# CANFD0_1.0 register map
Vendor: Texas Instruments
Registers are 32-bit, read-write, no defined reset value unless marked. A register's access mark holds for its fields unless they carry their own. Offsets are as the file gives them; [hi:lo] are bit positions; lines under a group give offsets from that group; {n}, {i} and the like mark numbered series.

## CANFD0 (part 2 of 3)
0x7000 CANFD0_MCAN group
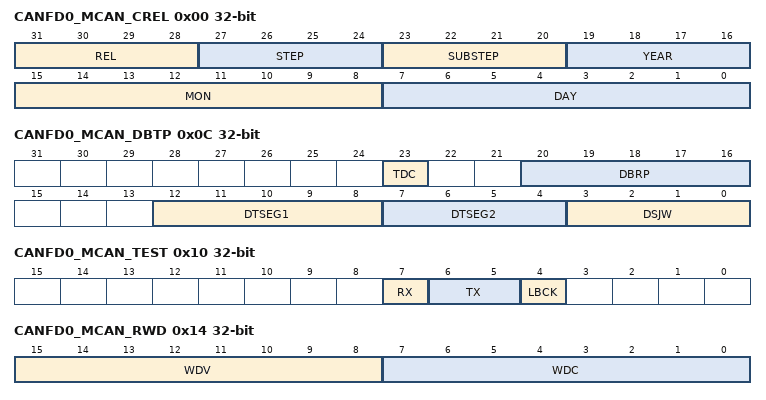
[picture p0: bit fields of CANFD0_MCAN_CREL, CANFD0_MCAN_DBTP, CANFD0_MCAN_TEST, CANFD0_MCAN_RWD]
  0x00 CANFD0_MCAN_CREL ro — MCAN Core Release Register
    [31:28] REL — Core Release. One digit, BCD-coded.
    [27:24] STEP — Step of Core Release. One digit, BCD-coded.
    [23:20] SUBSTEP — Sub-Step of Core Release. One digit, BCD-coded.
    [19:16] YEAR — Time Stamp Year. One digit, BCD-coded.
    [15:8] MON — Time Stamp Month. Two digits, BCD-coded.
    [7:0] DAY — Time Stamp Day. Two digits, BCD-coded.
  0x04 CANFD0_MCAN_ENDN access not given — MCAN Endian Register
  0x0C CANFD0_MCAN_DBTP — MCAN Data Bit Timing and Prescaler Register
    [23] TDC — Transmitter Delay Compensation 0 Transmitter Delay Compensation disabled 1 Transmitter Delay Compensation enabled
    [20:16] DBRP — Data Bit Rate Prescaler. The value by which the oscillator frequency is divided for generating the bit time quanta. The bit time is built up from a multiple of this quanta. Valid values for the Bit Rate Prescaler are 0 to 31. The actual interpretation by the hardware of this value is such that one more than the value programmed here is used. Qualified Write is possible only with CCCR.CCE='1' and CCCR.INIT='1'.
    [12:8] DTSEG1 — Data Time Segment Before Sample Point. Valid values are 0 to 31. The actual interpretation by the hardware of this value is such that one more than the programmed value is used. Qualified Write is possible only with CCCR.CCE='1' and CCCR.INIT='1'.
    [7:4] DTSEG2 — Data Time Segment After Sample Point. Valid values are 0 to 15. The actual interpretation by the hardware of this value is such that one more than the programmed value is used. Qualified Write is possible only with CCCR.CCE='1' and CCCR.INIT='1'.
    [3:0] DSJW — Data Resynchronization Jump Width. Valid values are 0 to 15. The actual interpretation by the hardware of this value is such that one more than the value programmed here is used. Qualified Write is possible only with CCCR.CCE='1' and CCCR.INIT='1'.
  0x10 CANFD0_MCAN_TEST access per field — MCAN Test Register
    [7] RX ro — Receive Pin. Monitors the actual value of the CAN receive pin.
      0=DOMINANT (The CAN bus is dominant (CAN RX pin = '0')); 1=RECESSIVE (The CAN bus is recessive (CAN RX pin = '1'))
    [6:5] TX rw — Control of Transmit Pin 00 CAN TX pin controlled by the CAN Core, updated at the end of the CAN bit time 01 Sample Point can be monitored at CAN TX pin 10 Dominant ('0') level at CAN TX pin 11 Recessive ('1') at CAN TX pin Qualified Write is possible only with CCCR.CCE='1' and CCCR.INIT='1'.
    [4] LBCK rw — Loop Back Mode. Qualified Write is possible only with CCCR.CCE='1' and CCCR.INIT='1'.
      0=DISABLE (Reset value, Loop Back Mode is disabled); 1=ENABLE (Loop Back Mode is enabled)
  0x14 CANFD0_MCAN_RWD access per field — MCAN RAM Watchdog
    [15:8] WDV ro — Watchdog Value. Acutal Message RAM Watchdog Counter Value. The RAM Watchdog monitors the READY output of the Message RAM. A Message RAM access via the MCAN's Generic Master Interface starts the Message RAM Watchdog Counter with the value configured by the WDC field. The counter is reloaded with WDC when the Message RAM signals successful completion by activating its READY output. In case there is no response from the Message RAM until the counter has counted down to zero, the counter stops and interrupt flag MCAN_IR.WDI is set. The RAM Watchdog Counter is clocked by the host (system) clock.
    [7:0] WDC rw — Watchdog Configuration. Start value of the Message RAM Watchdog Counter. With the reset value of "00" the counter is disabled. Qualified Write is possible only with CCCR.CCE='1' and CCCR.INIT='1'.
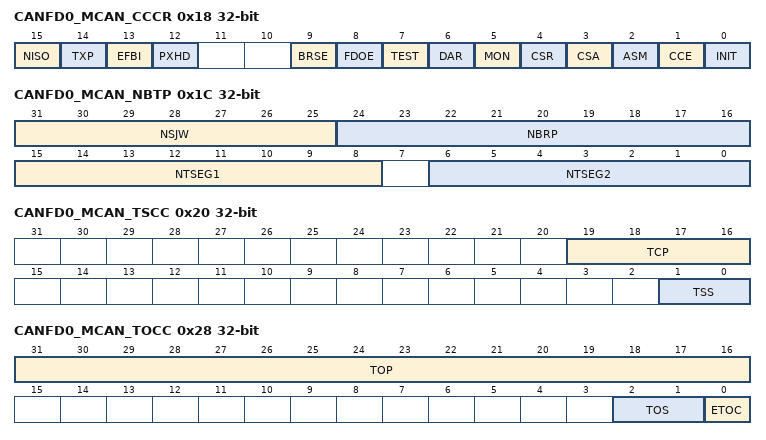
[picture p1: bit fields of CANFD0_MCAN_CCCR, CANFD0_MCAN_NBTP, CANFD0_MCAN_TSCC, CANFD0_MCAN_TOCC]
  0x18 CANFD0_MCAN_CCCR access per field — MCAN CC Control Register
    [15] NISO rw — Non ISO Operation. If this bit is set, the MCAN uses the CAN FD frame format as specified by the Bosch CAN FD Specification V1.0. 0 CAN FD frame format according to ISO 11898-1:2015 1 CAN FD frame format according to Bosch CAN FD Specification V1.0
    [14] TXP rw — Transmit Pause. If this bit is set, the MCAN pauses for two CAN bit times before starting the next transmission after itself has successfully transmitted a frame. 0 Transmit pause disabled 1 Transmit pause enabled Qualified Write is possible only with CCCR.CCE='1' and CCCR.INIT='1'.
    [13] EFBI rw — Edge Filtering during Bus Integration 0 Edge filtering disabled 1 Two consecutive dominant tq required to detect an edge for hard synchronization Qualified Write is possible only with CCCR.CCE='1' and CCCR.INIT='1'.
    [12] PXHD rw — Protocol Exception Handling Disable 0 Protocol exception handling enabled 1 Protocol exception handling disabled Note: When protocol exception handling is disabled, the MCAN will transmit an error frame when it detects a protocol exception condition. Qualified Write is possible only with CCCR.CCE='1' and CCCR.INIT='1'.
    [9] BRSE rw — Bit Rate Switch Enable 0 Bit rate switching for transmissions disabled 1 Bit rate switching for transmissions enabled Note: When CAN FD operation is disabled FDOE = '0', BRSE is not evaluated. Qualified Write is possible only with CCCR.CCE='1' and CCCR.INIT='1'.
    [8] FDOE rw — Flexible Datarate Operation Enable 0 FD operation disabled 1 FD operation enabled Qualified Write is possible only with CCCR.CCE='1' and CCCR.INIT='1'.
    [7] TEST rw — Test Mode Enable 0 Normal operation, register TEST holds reset values 1 Test Mode, write access to register TEST enabled Qualified Write 1 to Set is possible only with CCCR.CCE='1' and CCCR.INIT='1'.
    [6] DAR rw — Disable Automatic Retransmission 0 Automatic retransmission of messages not transmitted successfully enabled 1 Automatic retransmission disabled Qualified Write is possible only with CCCR.CCE='1' and CCCR.INIT='1'.
    [5] MON rw — Bus Monitoring Mode. Bit MON can only be set by SW when both CCE and INIT are set to '1'. The bit can be reset by SW at any time. 0 Bus Monitoring Mode is disabled 1 Bus Monitoring Mode is enabled Qualified Write 1 to Set is possible only with CCCR.CCE='1' and CCCR.INIT='1'.
    [4] CSR rw — Clock Stop Request 0 No clock stop is requested 1 Clock stop requested. When clock stop is requested, first INIT and then CSA will be set after all pending transfer requests have been completed and the CAN bus reached idle.
    [3] CSA ro — Clock Stop Acknowledge 0 No clock stop acknowledged 1 MCAN may be set in power down by stopping the Host and CAN clocks
    [2] ASM rw — Restricted Operation Mode. Bit ASM can only be set by SW when both CCE and INIT are set to '1'. The bit can be reset by SW at any time. 0 Normal CAN operation 1 Restricted Operation Mode active Qualified Write 1 to Set is possible only with CCCR.CCE='1' and CCCR.INIT='1'.
    [1] CCE rw — Configuration Change Enable 0 The CPU has no write access to the protected configuration registers 1 The CPU has write access to the protected configuration registers (while CCCR.INIT = '1') Qualified Write is possible only with CCCR.CCE='1' and CCCR.INIT='1'.
    [0] INIT rw — Initialization 0 Normal Operation 1 Initialization is started Note: Due to the synchronization mechanism between the two clock domains, there may be a delay until the value written to INIT can be read back. Therefore the programmer has to assure that the previous value written to INIT has been accepted by reading INIT before setting INIT to a new value.
  0x1C CANFD0_MCAN_NBTP — MCAN Nominal Bit Timing and Prescaler Register
    [31:25] NSJW — Nominal (Re)Synchronization Jump Width. Valid values are 0 to 127. The actual interpretation by the hardware of this value is such that one more than the value programmed here is used. Qualified Write is possible only with CCCR.CCE='1' and CCCR.INIT='1'.
    [24:16] NBRP — Nominal Bit Rate Prescaler. The value by which the oscillator frequency is divided for generating the bit time quanta. The bit time is built up from a multiple of this quanta. Valid values for the Bit Rate Prescaler are 0 to 511. The actual interpretation by the hardware of this value is such that one more than the value programmed here is used. Qualified Write is possible only with CCCR.CCE='1' and CCCR.INIT='1'.
    [15:8] NTSEG1 — Nominal Time Segment Before Sample Point. Valid values are 1 to 255. The actual interpretation by the hardware of this value is such that one more than the programmed value is used. Qualified Write is possible only with CCCR.CCE='1' and CCCR.INIT='1'.
    [6:0] NTSEG2 — Nominal Time Segment After Sample Point. Valid values are 1 to 127. The actual interpretation by the hardware of this value is such that one more than the programmed value is used. Qualified Write is possible only with CCCR.CCE='1' and CCCR.INIT='1'.
  0x20 CANFD0_MCAN_TSCC — MCAN Timestamp Counter Configuration
    [19:16] TCP — Timestamp Counter Prescaler. Configures the timestamp and timeout counters time unit in multiples of CAN bit times. Valid values are 0 to 15. The actual interpretation by the hardware of this value is such that one more than the value programmed here is used. Note: With CAN FD an external counter is required for timestamp generation (TSS = "10"). Qualified Write is possible only with CCCR.CCE='1' and CCCR.INIT='1'.
    [1:0] TSS — Timestamp Select 00 Timestamp counter value always 0x0000 01 Timestamp counter value incremented according to TCP 10 External timestamp counter value used 11 Same as "00" Qualified Write is possible only with CCCR.CCE='1' and CCCR.INIT='1'.
  0x24 CANFD0_MCAN_TSCV — MCAN Timestamp Counter Value
    [15:0] TSC — Timestamp Counter. The internal/external Timestamp Counter value is captured on start of frame (both Rx and Tx). When TSCC.TSS = "01", the Timestamp Counter is incremented in multiples of CAN bit times, (1...16), depending on the configuration of TSCC.TCP. A wrap around sets interrupt flag IR.TSW. Write access resets the counter to zero. When TSCC.TSS = "10", TSC reflects the External Timestamp Counter value, and a write access has no impact. Note: A "wrap around" is a change of the Timestamp Counter value from non-zero to zero not caused by write access to MCAN_TSCV.
  0x28 CANFD0_MCAN_TOCC — MCAN Timeout Counter Configuration
    [31:16] TOP — Timeout Period. Start value of the Timeout Counter (down-counter). Configures the Timeout Period. Qualified Write is possible only with CCCR.CCE='1' and CCCR.INIT='1'.
    [2:1] TOS — Timeout Select. When operating in Continuous mode, a write to TOCV presets the counter to the value configured by TOCC.TOP and continues down-counting. When the Timeout Counter is controlled by one of the FIFOs, an empty FIFO presets the counter to the value configured by TOCC.TOP. Down-counting is started when the first FIFO element is stored. 00 Continuous operation 01 Timeout controlled by Tx Event FIFO 10 Timeout controlled by Rx FIFO 0 11 Timeout controlled by Rx FIFO 1 Qualified Write is possible only with CCCR.CCE='1' and CCCR.INIT='1'.
    [0] ETOC — Enable Timeout Counter 0 Timeout Counter disabled 1 Timeout Counter enabled Qualified Write is possible only with CCCR.CCE='1' and CCCR.INIT='1'.
  0x2C CANFD0_MCAN_TOCV — MCAN Timeout Counter Value
    [15:0] TOC — Timeout Counter. The Timeout Counter is decremented in multiples of CAN bit times, (1...16), depending on the configuration of TSCC.TCP. When decremented to zero, interrupt flag IR.TOO is set and the Timeout Counter is stopped. Start and reset/restart conditions are configured via TOCC.TOS.
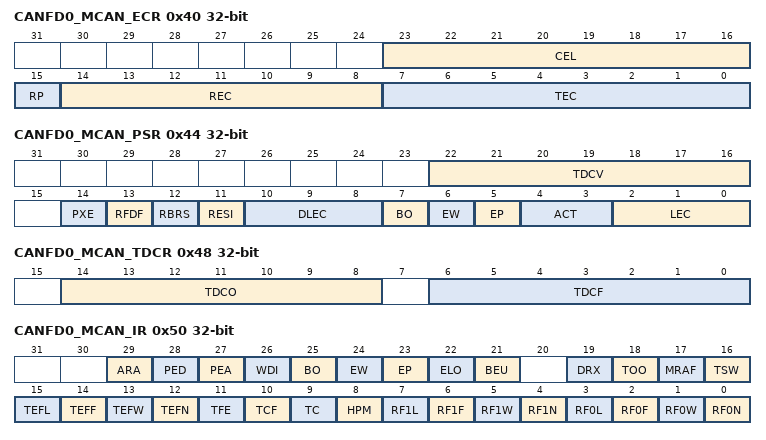
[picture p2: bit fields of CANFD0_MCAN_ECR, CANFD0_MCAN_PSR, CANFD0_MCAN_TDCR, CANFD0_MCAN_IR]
  0x40 CANFD0_MCAN_ECR ro — MCAN Error Counter Register
    [23:16] CEL — CAN Error Logging. The counter is incremented each time when a CAN protocol error causes the Transmit Error Counter or the Receive Error Counter to be incremented. It is reset by read access to CEL. The counter stops at 0xFF; the next increment of TEC or REC sets interrupt flag IR.ELO. Note: When CCCR.ASM is set, the CAN protocol controller does not increment TEC and REC when a CAN protocol error is detected, but CEL is still incremented.
    [15] RP — Receive Error Passive 0 The Receive Error Counter is below the error passive level of 128 1 The Receive Error Counter has reached the error passive level of 128
    [14:8] REC — Receive Error Counter. Actual state of the Receive Error Counter, values between 0 and 127. Note: When CCCR.ASM is set, the CAN protocol controller does not increment TEC and REC when a CAN protocol error is detected, but CEL is still incremented.
    [7:0] TEC — Transmit Error Counter. Actual state of the Transmit Error Counter, values between 0 and 255. Note: When CCCR.ASM is set, the CAN protocol controller does not increment TEC and REC when a CAN protocol error is detected, but CEL is still incremented.
  0x44 CANFD0_MCAN_PSR ro — MCAN Protocol Status Register
    [22:16] TDCV — Transmitter Delay Compensation Value. Position of the secondary sample point, defined by the sum of the measured delay from the internal CAN TX signal to the internal CAN RX signal and TDCR.TDCO. The SSP position is, in the data phase, the number of mtq between the start of the transmitted bit and the secondary sample point. Valid values are 0 to 127 mtq.
    [14] PXE — Protocol Exception Event 0 No protocol exception event occurred since last read access 1 Protocol exception event occurred
    [13] RFDF — Received a CAN FD Message. This bit is set independent of acceptance filtering. 0 Since this bit was reset by the CPU, no CAN FD message has been received 1 Message in CAN FD format with FDF flag set has been received
    [12] RBRS — BRS Flag of Last Received CAN FD Message. This bit is set together with RFDF, independent of acceptance filtering. 0 Last received CAN FD message did not have its BRS flag set 1 Last received CAN FD message had its BRS flag set
    [11] RESI — ESI Flag of Last Received CAN FD Message. This bit is set together with RFDF, independent of acceptance filtering. 0 Last received CAN FD message did not have its ESI flag set 1 Last received CAN FD message had its ESI flag set
    [10:8] DLEC — Data Phase Last Error Code. Type of last error that occurred in the data phase of a CAN FD format frame with its BRS flag set. Coding is the same as for LEC. This field will be cleared to zero when a CAN FD format frame with its BRS flag set has been transferred (reception or transmission) without error.
    [7] BO — Bus_Off Status 0 The M_CAN is not Bus_Off 1 The M_CAN is in Bus_Off state
    [6] EW — Warning Status 0 Both error counters are below the Error_Warning limit of 96 1 At least one of error counter has reached the Error_Warning limit of 96
    [5] EP — Error Passive 0 The M_CAN is in the Error_Active state. It normally takes part in bus communication and sends an active error flag when an error has been detected 1 The M_CAN is in the Error_Passive state
    [4:3] ACT — Node Activity. Monitors the module's CAN communication state. 00 Synchronizing - node is synchronizing on CAN communication 01 Idle - node is neither receiver nor transmitter 10 Receiver - node is operating as receiver 11 Transmitter - node is operating as transmitter Note: ACT is set to "00" by a Protocol Exception Event.
    [2:0] LEC — Last Error Code. The LEC indicates the type of the last error to occur on the CAN bus. This field will be cleared to '0' when a message has been transferred (reception or transmission) without error. 0 No Error: No error occurred since LEC has been reset by successful reception or transmission. 1 Stuff Error: More than 5 equal bits in a sequence have occurred in a part of a received message where this is not allowed. 2 Form Error: A fixed format part of a received frame has the wrong format. 3 AckError: The message transmitted by the MCAN was not acknowledged by another node. 4 Bit1Error: During the transmission of a message (with the exception of the arbitration field), the device wanted to send a recessive level (bit of logical value '1'), but the monitored bus value was dominant. 5 Bit0Error: During the transmission of a message (or acknowledge bit, or active error flag, or overload flag), the device wanted to send a dominant level (data or identifier bit logical value '0'), but the monitored bus value was recessive. During Bus_Off recovery this status is set each time a sequence of 11 recessive bits has been monitored. This enables the CPU to monitor the proceeding of the Bus_Off recovery sequence (indicating the bus is not stuck at dominant or continuously disturbed). 6 CRCError: The CRC check sum of a received message was incorrect. The CRC of an incoming message does not match with the CRC calculated from the received data. 7 NoChange: Any read access to the Protocol Status Register re-initializes the LEC to '7'. When the LEC shows the value '7', no CAN bus event was detected since the last CPU read access to the Protocol Status Register. Note: When a frame in CAN FD format has reached the data phase with BRS flag set, the next CAN event (error or valid frame) will be shown in DLEC instead of LEC. An error in a fixed stuff bit of a CAN FD CRC sequence will be shown as a Form Error, not Stuff Error. Note: The Bus_Off recovery sequence (see ISO 11898-1:2015) cannot be shortened by setting or resetting CCCR.INIT. If the device goes Bus_Off, it will set CCCR.INIT of its own accord, stopping all bus activities. Once CCCR.INIT has been cleared by the CPU, the device will then wait for 129 occurrences of Bus Idle (129 * 11 consecutive recessive bits) before resuming normal operation. At the end of the Bus_Off recovery sequence, the Error Management Counters will be reset. During the waiting time after the resetting of CCCR.INIT, each time a sequence of 11 recessive bits has been monitored, a Bit0Error code is written to PSR.LEC, enabling the CPU to readily check up whether the CAN bus is stuck at dominant or continuously disturbed and to monitor the Bus_Off recovery sequence. ECR.REC is used to count these sequences.
  0x48 CANFD0_MCAN_TDCR — MCAN Transmitter Delay Compensation Register
    [14:8] TDCO — Transmitter Delay Compensation Offset. Offset value defining the distance between the measured delay from the internal CAN TX signal to the internal CAN RX signal and the secondary sample point. Valid values are 0 to 127 mtq. Qualified Write is possible only with CCCR.CCE='1' and CCCR.INIT='1'.
    [6:0] TDCF — Transmitter Delay Compensation Filter Window Length. Defines the minimum value for the SSP position, dominant edges on the internal CAN RX signal that would result in an earlier SSP position are ignored for transmitter delay measurement. The feature is enabled when TDCF is configured to a value greater than TDCO. Valid values are 0 to 127 mtq. Qualified Write is possible only with CCCR.CCE='1' and CCCR.INIT='1'.
  0x50 CANFD0_MCAN_IR — MCAN Interrupt Register
    [29] ARA — Access to Reserved Address 0 No access to reserved address occurred 1 Access to reserved address occurred
    [28] PED — Protocol Error in Data Phase (Data Bit Time is used) 0 No protocol error in data phase 1 Protocol error in data phase detected (PSR.DLEC ? 0,7)
    [27] PEA — Protocol Error in Arbitration Phase (Nominal Bit Time is used) 0 No protocol error in arbitration phase 1 Protocol error in arbitration phase detected (PSR.LEC ? 0,7)
    [26] WDI — Watchdog Interrupt 0 No Message RAM Watchdog event occurred 1 Message RAM Watchdog event due to missing READY
    [25] BO — Bus_Off Status 0 Bus_Off status unchanged 1 Bus_Off status changed
    [24] EW — Warning Status 0 Error_Warning status unchanged 1 Error_Warning status changed
    [23] EP — Error Passive 0 Error_Passive status unchanged 1 Error_Passive status changed
    [22] ELO — Error Logging Overflow 0 CAN Error Logging Counter did not overflow 1 Overflow of CAN Error Logging Counter occurred
    [21] BEU — Bit Error Uncorrected. Message RAM bit error detected, uncorrected. This bit is set when a double bit error is detected by the ECC aggregator attached to the Message RAM. An uncorrected Message RAM bit error sets CCCR.INIT to '1'. This is done to avoid transmission of corrupted data. 0 No bit error detected when reading from Message RAM 1 Bit error detected, uncorrected (e.g. parity logic)
    [19] DRX — Message Stored to Dedicated Rx Buffer. The flag is set whenever a received message has been stored into a dedicated Rx Buffer. 0 No Rx Buffer updated 1 At least one received message stored into an Rx Buffer
    [18] TOO — Timeout Occurred 0 No timeout 1 Timeout reached
    [17] MRAF — Message RAM Access Failure. The flag is set, when the Rx Handler: - has not completed acceptance filtering or storage of an accepted message until the arbitration field of the following message has been received. In this case acceptance filtering or message storage is aborted and the Rx Handler starts processing of the following message. - was not able to write a message to the Message RAM. In this case message storage is aborted. In both cases the FIFO put index is not updated resp. the New Data flag for a dedicated Rx Buffer is not set, a partly stored message is overwritten when the next message is stored to this location. The flag is also set when the Tx Handler was not able to read a message from the Message RAM in time. In this case message transmission is aborted. In case of a Tx Handler access failure the MCAN is switched into Restricted Operation Mode. To leave Restricted Operation Mode, the Host CPU has to reset CCCR.ASM. 0 No Message RAM access failure occurred 1 Message RAM access failure occurred
    [16] TSW — Timestamp Wraparound 0 No timestamp counter wrap-around 1 Timestamp counter wrapped around
    [15] TEFL — Tx Event FIFO Element Lost 0 No Tx Event FIFO element lost 1 Tx Event FIFO element lost, also set after write attempt to Tx Event FIFO of size zero
    [14] TEFF — Tx Event FIFO Full 0 Tx Event FIFO not full 1 Tx Event FIFO full
    [13] TEFW — Tx Event FIFO Watermark Reached 0 Tx Event FIFO fill level below watermark 1 Tx Event FIFO fill level reached watermark
    [12] TEFN — Tx Event FIFO New Entry 0 Tx Event FIFO unchanged 1 Tx Handler wrote Tx Event FIFO element
    [11] TFE — Tx FIFO Empty 0 Tx FIFO non-empty 1 Tx FIFO empty
    [10] TCF — Transmission Cancellation Finished 0 No transmission cancellation finished 1 Transmission cancellation finished
    [9] TC — Transmission Completed 0 No transmission completed 1 Transmission completed
    [8] HPM — High Priority Message 0 No high priority message received 1 High priority message received
    [7] RF1L — Rx FIFO 1 Message Lost 0 No Rx FIFO 1 message lost 1 Rx FIFO 1 message lost, also set after write attempt to Rx FIFO 1 of size zero
    [6] RF1F — Rx FIFO 1 Full 0 Rx FIFO 1 not full 1 Rx FIFO 1 full
    [5] RF1W — Rx FIFO 1 Watermark Reached 0 Rx FIFO 1 fill level below watermark 1 Rx FIFO 1 fill level reached watermark
    [4] RF1N — Rx FIFO 1 New Message 0 No new message written to Rx FIFO 1 1 New message written to Rx FIFO 1
    [3] RF0L — Rx FIFO 0 Message Lost 0 No Rx FIFO 0 message lost 1 Rx FIFO 0 message lost, also set after write attempt to Rx FIFO 0 of size zero
    [2] RF0F — Rx FIFO 0 Full 0 Rx FIFO 0 not full 1 Rx FIFO 0 full
    [1] RF0W — Rx FIFO 0 Watermark Reached 0 Rx FIFO 0 fill level below watermark 1 Rx FIFO 0 fill level reached watermark
    [0] RF0N — Rx FIFO 0 New Message 0 No new message written to Rx FIFO 0 1 New message written to Rx FIFO 0
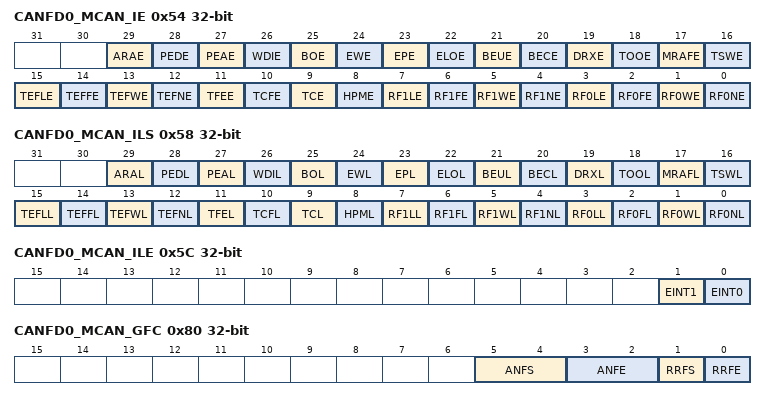
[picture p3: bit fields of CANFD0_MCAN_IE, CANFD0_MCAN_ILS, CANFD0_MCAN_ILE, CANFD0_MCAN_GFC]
  0x54 CANFD0_MCAN_IE — MCAN Interrupt Enable
    [29] ARAE — Access to Reserved Address Enable
    [28] PEDE — Protocol Error in Data Phase Enable
    [27] PEAE — Protocol Error in Arbitration Phase Enable
    [26] WDIE — Watchdog Interrupt Enable
    [25] BOE — Bus_Off Status Enable
    [24] EWE — Warning Status Enable
    [23] EPE — Error Passive Enable
    [22] ELOE — Error Logging Overflow Enable
    [21] BEUE — Bit Error Uncorrected Enable
    [20] BECE — Bit Error Corrected Enable A separate interrupt line reserved for corrected bit errors is provided via the MCAN_ERROR_REGS. It advised for the user to use these registers and leave this bit cleared to '0'.
    [19] DRXE — Message Stored to Dedicated Rx Buffer Enable
    [18] TOOE — Timeout Occurred Enable
    [17] MRAFE — Message RAM Access Failure Enable
    [16] TSWE — Timestamp Wraparound Enable
    [15] TEFLE — Tx Event FIFO Element Lost Enable
    [14] TEFFE — Tx Event FIFO Full Enable
    [13] TEFWE — Tx Event FIFO Watermark Reached Enable
    [12] TEFNE — Tx Event FIFO New Entry Enable
    [11] TFEE — Tx FIFO Empty Enable
    [10] TCFE — Transmission Cancellation Finished Enable
    [9] TCE — Transmission Completed Enable
    [8] HPME — High Priority Message Enable
    [7] RF1LE — Rx FIFO 1 Message Lost Enable
    [6] RF1FE — Rx FIFO 1 Full Enable
    [5] RF1WE — Rx FIFO 1 Watermark Reached Enable
    [4] RF1NE — Rx FIFO 1 New Message Enable
    [3] RF0LE — Rx FIFO 0 Message Lost Enable
    [2] RF0FE — Rx FIFO 0 Full Enable
    [1] RF0WE — Rx FIFO 0 Watermark Reached Enable
    [0] RF0NE — Rx FIFO 0 New Message Enable
  0x58 CANFD0_MCAN_ILS — MCAN Interrupt Line Select
    [29] ARAL — Access to Reserved Address Line 0 Interrupt source is assigned to Interrupt Line 0 1 Interrupt source is assigned to Interrupt Line 1
    [28] PEDL — Protocol Error in Data Phase Line 0 Interrupt source is assigned to Interrupt Line 0 1 Interrupt source is assigned to Interrupt Line 1
    [27] PEAL — Protocol Error in Arbitration Phase Line 0 Interrupt source is assigned to Interrupt Line 0 1 Interrupt source is assigned to Interrupt Line 1
    [26] WDIL — Watchdog Interrupt Line 0 Interrupt source is assigned to Interrupt Line 0 1 Interrupt source is assigned to Interrupt Line 1
    [25] BOL — Bus_Off Status Line 0 Interrupt source is assigned to Interrupt Line 0 1 Interrupt source is assigned to Interrupt Line 1
    [24] EWL — Warning Status Line 0 Interrupt source is assigned to Interrupt Line 0 1 Interrupt source is assigned to Interrupt Line 1
    [23] EPL — Error Passive Line 0 Interrupt source is assigned to Interrupt Line 0 1 Interrupt source is assigned to Interrupt Line 1
    [22] ELOL — Error Logging Overflow Line 0 Interrupt source is assigned to Interrupt Line 0 1 Interrupt source is assigned to Interrupt Line 1
    [21] BEUL — Bit Error Uncorrected Line 0 Interrupt source is assigned to Interrupt Line 0 1 Interrupt source is assigned to Interrupt Line 1
    [20] BECL — Bit Error Corrected Line A separate interrupt line reserved for corrected bit errors is provided via the MCAN_ERROR_REGS. It advised for the user to use these registers and leave the MCAN_IE.BECE bit cleared to '0' (disabled), thereby relegating this bit to not applicable.
    [19] DRXL — Message Stored to Dedicated Rx Buffer Line 0 Interrupt source is assigned to Interrupt Line 0 1 Interrupt source is assigned to Interrupt Line 1
    [18] TOOL — Timeout Occurred Line 0 Interrupt source is assigned to Interrupt Line 0 1 Interrupt source is assigned to Interrupt Line 1
    [17] MRAFL — Message RAM Access Failure Line 0 Interrupt source is assigned to Interrupt Line 0 1 Interrupt source is assigned to Interrupt Line 1
    [16] TSWL — Timestamp Wraparound Line 0 Interrupt source is assigned to Interrupt Line 0 1 Interrupt source is assigned to Interrupt Line 1
    [15] TEFLL — Tx Event FIFO Element Lost Line 0 Interrupt source is assigned to Interrupt Line 0 1 Interrupt source is assigned to Interrupt Line 1
    [14] TEFFL — Tx Event FIFO Full Line 0 Interrupt source is assigned to Interrupt Line 0 1 Interrupt source is assigned to Interrupt Line 1
    [13] TEFWL — Tx Event FIFO Watermark Reached Line 0 Interrupt source is assigned to Interrupt Line 0 1 Interrupt source is assigned to Interrupt Line 1
    [12] TEFNL — Tx Event FIFO New Entry Line 0 Interrupt source is assigned to Interrupt Line 0 1 Interrupt source is assigned to Interrupt Line 1
    [11] TFEL — Tx FIFO Empty Line 0 Interrupt source is assigned to Interrupt Line 0 1 Interrupt source is assigned to Interrupt Line 1
    [10] TCFL — Transmission Cancellation Finished Line 0 Interrupt source is assigned to Interrupt Line 0 1 Interrupt source is assigned to Interrupt Line 1
    [9] TCL — Transmission Completed Line 0 Interrupt source is assigned to Interrupt Line 0 1 Interrupt source is assigned to Interrupt Line 1
    [8] HPML — High Priority Message Line 0 Interrupt source is assigned to Interrupt Line 0 1 Interrupt source is assigned to Interrupt Line 1
    [7] RF1LL — Rx FIFO 1 Message Lost Line 0 Interrupt source is assigned to Interrupt Line 0 1 Interrupt source is assigned to Interrupt Line 1
    [6] RF1FL — Rx FIFO 1 Full Line 0 Interrupt source is assigned to Interrupt Line 0 1 Interrupt source is assigned to Interrupt Line 1
    [5] RF1WL — Rx FIFO 1 Watermark Reached Line 0 Interrupt source is assigned to Interrupt Line 0 1 Interrupt source is assigned to Interrupt Line 1
    [4] RF1NL — Rx FIFO 1 New Message Line 0 Interrupt source is assigned to Interrupt Line 0 1 Interrupt source is assigned to Interrupt Line 1
    [3] RF0LL — Rx FIFO 0 Message Lost Line 0 Interrupt source is assigned to Interrupt Line 0 1 Interrupt source is assigned to Interrupt Line 1
    [2] RF0FL — Rx FIFO 0 Full Line 0 Interrupt source is assigned to Interrupt Line 0 1 Interrupt source is assigned to Interrupt Line 1
    [1] RF0WL — Rx FIFO 0 Watermark Reached Line 0 Interrupt source is assigned to Interrupt Line 0 1 Interrupt source is assigned to Interrupt Line 1
    [0] RF0NL — Rx FIFO 0 New Message Line 0 Interrupt source is assigned to Interrupt Line 0 1 Interrupt source is assigned to Interrupt Line 1
  0x5C CANFD0_MCAN_ILE — MCAN Interrupt Line Enable
    [1] EINT1 — Enable Interrupt Line 1 0 Interrupt Line 1 is disabled 1 Interrupt Line 1 is enabled
    [0] EINT0 — Enable Interrupt Line 0 0 Interrupt Line 0 is disabled 1 Interrupt Line 0 is enabled
  0x80 CANFD0_MCAN_GFC — MCAN Global Filter Configuration
    [5:4] ANFS — Accept Non-matching Frames Standard. Defines how received messages with 11-bit IDs that do not match any element of the filter list are treated. 00 Accept in Rx FIFO 0 01 Accept in Rx FIFO 1 10 Reject 11 Reject Qualified Write is possible only with CCCR.CCE='1' and CCCR.INIT='1'.
    [3:2] ANFE — Accept Non-matching Frames Extended. Defines how received messages with 29-bit IDs that do not match any element of the filter list are treated. 00 Accept in Rx FIFO 0 01 Accept in Rx FIFO 1 10 Reject 11 Reject Qualified Write is possible only with CCCR.CCE='1' and CCCR.INIT='1'.
    [1] RRFS — Reject Remote Frames Standard 0 Filter remote frames with 11-bit standard IDs 1 Reject all remote frames with 11-bit standard IDs Qualified Write is possible only with CCCR.CCE='1' and CCCR.INIT='1'.
    [0] RRFE — Reject Remote Frames Extended 0 Filter remote frames with 29-bit extended IDs 1 Reject all remote frames with 29-bit extended IDs Qualified Write is possible only with CCCR.CCE='1' and CCCR.INIT='1'.
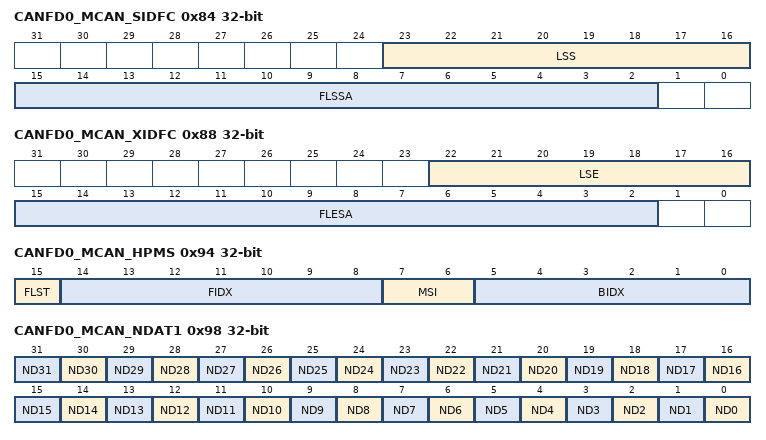
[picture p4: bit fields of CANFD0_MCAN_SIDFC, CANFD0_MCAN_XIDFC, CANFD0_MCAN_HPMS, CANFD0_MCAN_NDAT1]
  0x84 CANFD0_MCAN_SIDFC — MCAN Standard ID Filter Configuration
    [23:16] LSS — List Size Standard 0 No standard Message ID filter 1-128 Number of standard Message ID filter elements >128 Values greater than 128 are interpreted as 128
    [15:2] FLSSA — Filter List Standard Start Address. Start address of standard Message ID filter list (32-bit word address).
  0x88 CANFD0_MCAN_XIDFC — MCAN Extended ID Filter Configuration
    [22:16] LSE — Filter List Extended Start Address. Start address of extended Message ID filter list (32-bit word address). Qualified Write is possible only with CCCR.CCE='1' and CCCR.INIT='1'.
    [15:2] FLESA — List Size Extended 0 No extended Message ID filter 1-64 Number of extended Message ID filter elements >64 Values greater than 64 are interpreted as 64 Qualified Write is possible only with CCCR.CCE='1' and CCCR.INIT='1'.
  0x90 CANFD0_MCAN_XIDAM — MCAN Extended ID and Mask
    [28:0] EIDM — Extended ID Mask. For acceptance filtering of extended frames the Extended ID AND Mask is ANDed with the Message ID of a received frame. Intended for masking of 29-bit IDs in SAE J1939. With the reset value of all bits set to one the mask is not active. Qualified Write is possible only with CCCR.CCE='1' and CCCR.INIT='1'.
  0x94 CANFD0_MCAN_HPMS ro — MCAN High Priority Message Status
    [15] FLST — Filter List. Indicates the filter list of the matching filter element. 0 Standard Filter List 1 Extended Filter List
    [14:8] FIDX — Filter Index. Index of matching filter element. Range is 0 to SIDFC.LSS - 1 resp. XIDFC.LSE - 1.
    [7:6] MSI — Message Storage Indicator 00 No FIFO selected 01 FIFO message lost 10 Message stored in FIFO 0 11 Message stored in FIFO 1
    [5:0] BIDX — Buffer Index. Index of Rx FIFO element to which the message was stored. Only valid when MSI(1) = '1'.
  0x98 CANFD0_MCAN_NDAT1 — MCAN New Data 1
    [n] ND{n} (n=0..31) — New Data RX Buffer {n} 0 Rx Buffer not updated 1 Rx Buffer updated from new message
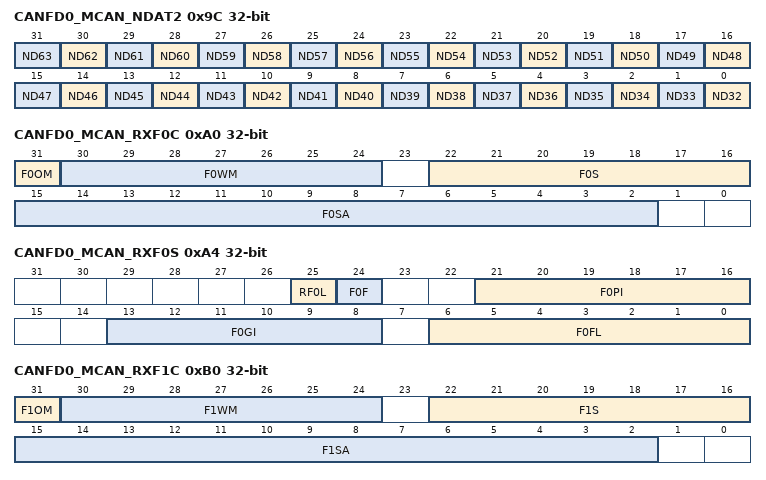
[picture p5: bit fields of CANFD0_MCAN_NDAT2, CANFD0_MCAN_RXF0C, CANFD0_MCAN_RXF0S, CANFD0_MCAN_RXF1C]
  0x9C CANFD0_MCAN_NDAT2 — MCAN New Data 2
    [n-32] ND{n} (n=32..63) — New Data RX Buffer {n} 0 Rx Buffer not updated 1 Rx Buffer updated from new message
  0xA0 CANFD0_MCAN_RXF0C — MCAN Rx FIFO 0 Configuration
    [31] F0OM — FIFO 0 Operation Mode. FIFO 0 can be operated in blocking or in overwrite mode. 0 FIFO 0 blocking mode 1 FIFO 0 overwrite mode Qualified Write is possible only with CCCR.CCE='1' and CCCR.INIT='1'.
    [30:24] F0WM — Rx FIFO 0 Watermark 0 Watermark interrupt disabled 1-64 Level for Rx FIFO 0 watermark interrupt (IR.RF0W) >64 Watermark interrupt disabled Qualified Write is possible only with CCCR.CCE='1' and CCCR.INIT='1'.
    [22:16] F0S — Rx FIFO 0 Size. The Rx FIFO 0 elements are indexed from 0 to F0S-1. 0 No Rx FIFO 0 1-64 Number of Rx FIFO 0 elements >64 Values greater than 64 are interpreted as 64 Qualified Write is possible only with CCCR.CCE='1' and CCCR.INIT='1'.
    [15:2] F0SA — Rx FIFO 0 Start Address. Start address of Rx FIFO 0 in Message RAM (32-bit word address). Qualified Write is possible only with CCCR.CCE='1' and CCCR.INIT='1'.
  0xA4 CANFD0_MCAN_RXF0S ro — MCAN Rx FIFO 0 Status
    [25] RF0L — Rx FIFO 0 Message Lost. This bit is a copy of interrupt flag IR.RF0L. When IR.RF0L is reset, this bit is also reset. 0 No Rx FIFO 0 message lost 1 Rx FIFO 0 message lost, also set after write attempt to Rx FIFO 0 of size zero Note: Overwriting the oldest message when RXF0C.F0OM = '1' will not set this flag.
    [24] F0F — Rx FIFO 0 Full 0 Rx FIFO 0 not full 1 Rx FIFO 0 full
    [21:16] F0PI — Rx FIFO 0 Put Index. Rx FIFO 0 write index pointer, range 0 to 63.
    [13:8] F0GI — Rx FIFO 0 Get Index. Rx FIFO 0 read index pointer, range 0 to 63.
    [6:0] F0FL — Rx FIFO 0 Fill Level. Number of elements stored in Rx FIFO 0, range 0 to 64.
  0xA8 CANFD0_MCAN_RXF0A — MCAN Rx FIFO 0 Acknowledge
    [5:0] F0AI — Rx FIFO 0 Acknowledge Index. After the Host has read a message or a sequence of messages from Rx FIFO 0 it has to write the buffer index of the last element read from Rx FIFO 0 to F0AI. This will set the Rx FIFO 0 Get Index RXF0S.F0GI to F0AI + 1 and update the FIFO 0 Fill Level RXF0S.F0FL.
  0xAC CANFD0_MCAN_RXBC — MCAN Rx Buffer Configuration
    [15:2] RBSA — Rx Buffer Start Address. Configures the start address of the Rx Buffers section in the Message RAM (32-bit word address). +I466
  0xB0 CANFD0_MCAN_RXF1C — MCAN Rx FIFO 1 Configuration
    [31] F1OM — FIFO 1 Operation Mode. FIFO 1 can be operated in blocking or in overwrite mode. 0 FIFO 1 blocking mode 1 FIFO 1 overwrite mode Qualified Write is possible only with CCCR.CCE='1' and CCCR.INIT='1'.
    [30:24] F1WM — Rx FIFO 1 Watermark 0 Watermark interrupt disabled 1-64 Level for Rx FIFO 1 watermark interrupt (IR.RF1W) >64 Watermark interrupt disabled Qualified Write is possible only with CCCR.CCE='1' and CCCR.INIT='1'.
    [22:16] F1S — Rx FIFO 1 Size. The Rx FIFO 1 elements are indexed from 0 to F1S - 1. 0 No Rx FIFO 1 1-64 Number of Rx FIFO 1 elements >64 Values greater than 64 are interpreted as 64 Qualified Write is possible only with CCCR.CCE='1' and CCCR.INIT='1'.
    [15:2] F1SA — Rx FIFO 1 Start Address Start address of Rx FIFO 1 in Message RAM (32-bit word address).
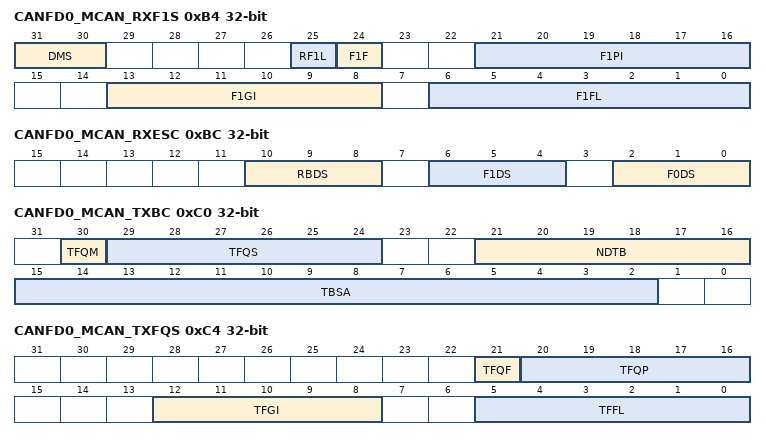
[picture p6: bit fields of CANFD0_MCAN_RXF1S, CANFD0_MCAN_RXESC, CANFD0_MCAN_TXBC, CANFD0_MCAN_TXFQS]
  0xB4 CANFD0_MCAN_RXF1S ro — MCAN Rx FIFO 1 Status
    [31:30] DMS — Debug Message Status 00 Idle state, wait for reception of debug messages 01 Debug message A received 10 Debug messages A, B received 11 Debug messages A, B, C received
    [25] RF1L — Rx FIFO 1 Message Lost. This bit is a copy of interrupt flag IR.RF1L. When IR.RF1L is reset, this bit is also reset. 0 No Rx FIFO 1 message lost 1 Rx FIFO 1 message lost, also set after write attempt to Rx FIFO 1 of size zero Note: Overwriting the oldest message when RXF1C.F1OM = '1' will not set this flag.
    [24] F1F — Rx FIFO 1 Full 0 Rx FIFO 1 not full 1 Rx FIFO 1 full
    [21:16] F1PI — Rx FIFO 1 Put Index. Rx FIFO 1 write index pointer, range 0 to 63.
    [13:8] F1GI — Rx FIFO 1 Get Index. Rx FIFO 1 read index pointer, range 0 to 63.
    [6:0] F1FL — Rx FIFO 1 Fill Level. Number of elements stored in Rx FIFO 1, range 0 to 64.
  0xB8 CANFD0_MCAN_RXF1A — MCAN Rx FIFO 1 Acknowledge
    [5:0] F1AI — Rx FIFO 1 Acknowledge Index. After the Host has read a message or a sequence of messages from Rx FIFO 1 it has to write the buffer index of the last element read from Rx FIFO 1 to F1AI. This will set the Rx FIFO 1 Get Index RXF1S.F1GI to F1AI + 1 and update the FIFO 1 Fill Level RXF1S.F1FL.
  0xBC CANFD0_MCAN_RXESC — MCAN Rx Buffer / FIFO Element Size Configuration
    [10:8] RBDS — Rx Buffer Data Field Size 000 8 byte data field 001 12 byte data field 010 16 byte data field 011 20 byte data field 100 24 byte data field 101 32 byte data field 110 48 byte data field 111 64 byte data field Note: In case the data field size of an accepted CAN frame exceeds the data field size configured for the matching Rx Buffer or Rx FIFO, only the number of bytes as configured by RXESC are stored to the Rx Buffer resp. Rx FIFO element. The rest of the frame's data field is ignored. Qualified Write is possible only with CCCR.CCE='1' and CCCR.INIT='1'.
    [6:4] F1DS — Rx FIFO 1 Data Field Size 000 8 byte data field 001 12 byte data field 010 16 byte data field 011 20 byte data field 100 24 byte data field 101 32 byte data field 110 48 byte data field 111 64 byte data field Note: In case the data field size of an accepted CAN frame exceeds the data field size configured for the matching Rx Buffer or Rx FIFO, only the number of bytes as configured by RXESC are stored to the Rx Buffer resp. Rx FIFO element. The rest of the frame's data field is ignored. Qualified Write is possible only with CCCR.CCE='1' and CCCR.INIT='1'.
    [2:0] F0DS — Rx FIFO 0 Data Field Size 000 8 byte data field 001 12 byte data field 010 16 byte data field 011 20 byte data field 100 24 byte data field 101 32 byte data field 110 48 byte data field 111 64 byte data field Note: In case the data field size of an accepted CAN frame exceeds the data field size configured for the matching Rx Buffer or Rx FIFO, only the number of bytes as configured by RXESC are stored to the Rx Buffer resp. Rx FIFO element. The rest of the frame's data field is ignored. Qualified Write is possible only with CCCR.CCE='1' and CCCR.INIT='1'.
  0xC0 CANFD0_MCAN_TXBC — MCAN Tx Buffer Configuration
    [30] TFQM — Tx FIFO/Queue Mode 0 Tx FIFO operation 1 Tx Queue operation Qualified Write is possible only with CCCR.CCE='1' and CCCR.INIT='1'.
    [29:24] TFQS — Transmit FIFO/Queue Size 0 No Tx FIFO/Queue 1-32 Number of Tx Buffers used for Tx FIFO/Queue >32 Values greater than 32 are interpreted as 32 Note: Be aware that the sum of TFQS and NDTB may be not greater than 32. There is no check for erroneous configurations. The Tx Buffers section in the Message RAM starts with the dedicated Tx Buffers. Qualified Write is possible only with CCCR.CCE='1' and CCCR.INIT='1'.
    [21:16] NDTB — Number of Dedicated Transmit Buffers 0 No Dedicated Tx Buffers 1-32 Number of Dedicated Tx Buffers >32 Values greater than 32 are interpreted as 32 Note: Be aware that the sum of TFQS and NDTB may be not greater than 32. There is no check for erroneous configurations. The Tx Buffers section in the Message RAM starts with the dedicated Tx Buffers. Qualified Write is possible only with CCCR.CCE='1' and CCCR.INIT='1'.
    [15:2] TBSA — Tx Buffers Start Address. Start address of Tx Buffers section in Message RAM (32-bit word address). Qualified Write is possible only with CCCR.CCE='1' and CCCR.INIT='1'.
  0xC4 CANFD0_MCAN_TXFQS ro — MCAN Tx FIFO / Queue Status
    [21] TFQF — Tx FIFO/Queue Full 0 Tx FIFO/Queue not full 1 Tx FIFO/Queue full
    [20:16] TFQP — Tx FIFO/Queue Put Index. Tx FIFO/Queue write index pointer, range 0 to 31. Note: In case of mixed configurations where dedicated Tx Buffers are combined with a Tx FIFO or a Tx Queue, the Put and Get Indices indicate the number of the Tx Buffer starting with the first dedicated Tx Buffers. Example: For a configuration of 12 dedicated Tx Buffers and a Tx FIFO of 20 Buffers a Put Index of 15 points to the fourth buffer of the Tx FIFO.
    [12:8] TFGI — Tx FIFO Get Index. Tx FIFO read index pointer, range 0 to 31. Read as zero when Tx Queue operation is configured (TXBC.TFQM = '1'). Note: In case of mixed configurations where dedicated Tx Buffers are combined with a Tx FIFO or a Tx Queue, the Put and Get Indices indicate the number of the Tx Buffer starting with the first dedicated Tx Buffers. Example: For a configuration of 12 dedicated Tx Buffers and a Tx FIFO of 20 Buffers a Put Index of 15 points to the fourth buffer of the Tx FIFO.
    [5:0] TFFL — Tx FIFO Free Level. Number of consecutive free Tx FIFO elements starting from TFGI, range 0 to 32. Read as zero when Tx Queue operation is configured (TXBC.TFQM = '1').
  0xC8 CANFD0_MCAN_TXESC — MCAN Tx Buffer Element Size Configuration
    [2:0] TBDS — Tx Buffer Data Field Size 000 8 byte data field 001 12 byte data field 010 16 byte data field 011 20 byte data field 100 24 byte data field 101 32 byte data field 110 48 byte data field 111 64 byte data field Note: In case the data length code DLC of a Tx Buffer element is configured to a value higher than the Tx Buffer data field size TXESC.TBDS, the bytes not defined by the Tx Buffer are transmitted as "0xCC" (padding bytes). Qualified Write is possible only with CCCR.CCE='1' and CCCR.INIT='1'.
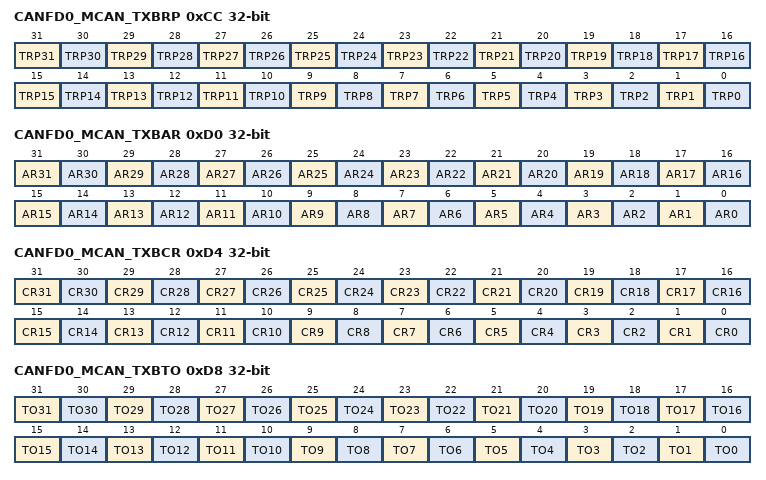
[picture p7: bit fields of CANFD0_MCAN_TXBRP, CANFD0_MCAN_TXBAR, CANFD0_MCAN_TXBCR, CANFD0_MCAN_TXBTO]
  0xCC CANFD0_MCAN_TXBRP ro — MCAN Tx Buffer Request Pending
    [n] TRP{n} (n=1..31) — Transmission Request Pending {n}. See description for bit 0.
    [0] TRP0 — Transmission Request Pending 0. Each Tx Buffer has its own Transmission Request Pending bit. The bits are set via register TXBAR. The bits are reset after a requested transmission has completed or has been cancelled via register TXBCR. TXBRP bits are set only for those Tx Buffers configured via TXBC. After a TXBRP bit has been set, a Tx scan is started to check for the pending Tx request with the highest priority (Tx Buffer with lowest Message ID). A cancellation request resets the corresponding transmission request pending bit of register TXBRP. In case a transmission has already been started when a cancellation is requested, this is done at the end of the transmission, regardless whether the transmission was successful or not. The cancellation request bits are reset directly after the corresponding TXBRP bit has been reset. After a cancellation has been requested, a finished cancellation is signalled via TXBCF - after successful transmission together with the corresponding TXBTO bit - when the transmission has not yet been started at the point of cancellation - when the transmission has been aborted due to lost arbitration - when an error occurred during frame transmission In DAR mode all transmissions are automatically cancelled if they are not successful. The corresponding TXBCF bit is set for all unsuccessful transmissions. 0 No transmission request pending 1 Transmission request pending Note: TXBRP bits which are set while a Tx scan is in progress are not considered during this particular Tx scan. In case a cancellation is requested for such a Tx Buffer, this Add Request is cancelled immediately, the corresponding TXBRP bit is reset.
  0xD0 CANFD0_MCAN_TXBAR — MCAN Tx Buffer Add Request
    [n] AR{n} (n=1..31) — Add Request {n}. See description for bit 0.
    [0] AR0 — Add Request 0. Each Tx Buffer has its own Add Request bit. Writing a '1' will set the corresponding Add Request bit; writing a '0' has no impact. This enables the Host to set transmission requests for multiple Tx Buffers with one write to TXBAR. TXBAR bits are set only for those Tx Buffers configured via TXBC. When no Tx scan is running, the bits are reset immediately, else the bits remain set until the Tx scan process has completed. 0 No transmission request added 1 Transmission requested added Note: If an add request is applied for a Tx Buffer with pending transmission request (corresponding TXBRP bit already set), this add request is ignored. Qualified Write is possible only with CCCR.CCE='0'
  0xD4 CANFD0_MCAN_TXBCR — MCAN Tx Buffer Cancellation Request
    [n] CR{n} (n=1..31) — Cancellation Request {n}. See description for bit 0.
    [0] CR0 — Cancellation Request 0. Each Tx Buffer has its own Cancellation Request bit. Writing a '1' will set the corresponding Cancellation Request bit; writing a '0' has no impact. This enables the Host to set cancellation requests for multiple Tx Buffers with one write to TXBCR. TXBCR bits are set only for those Tx Buffers configured via TXBC. The bits remain set until the corresponding bit of TXBRP is reset. 0 No cancellation pending 1 Cancellation pending Qualified Write is possible only with CCCR.CCE='0'
  0xD8 CANFD0_MCAN_TXBTO ro — MCAN Tx Buffer Transmission Occurred
    [n] TO{n} (n=1..31) — Transmission Occurred {n}. See description for bit 0.
    [0] TO0 — Transmission Occurred 0. Each Tx Buffer has its own Transmission Occurred bit. The bits are set when the corresponding TXBRP bit is cleared after a successful transmission. The bits are reset when a new transmission is requested by writing a '1' to the corresponding bit of register TXBAR. 0 No transmission occurred 1 Transmission occurred
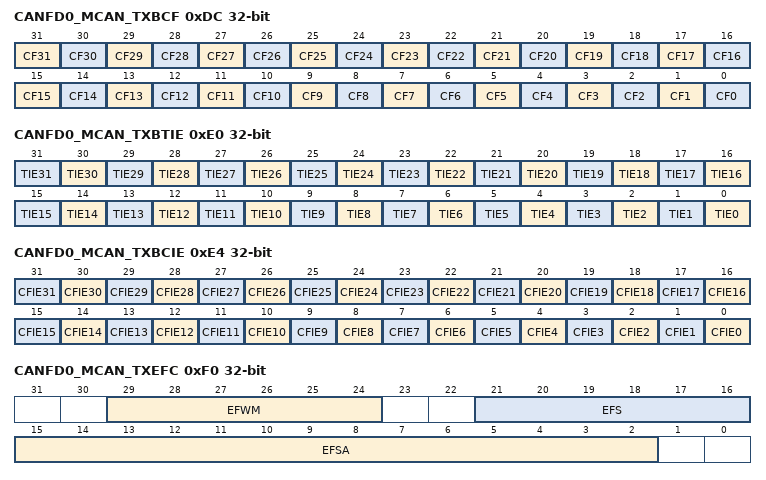
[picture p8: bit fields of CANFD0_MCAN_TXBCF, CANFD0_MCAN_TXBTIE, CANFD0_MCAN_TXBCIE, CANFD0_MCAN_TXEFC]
  0xDC CANFD0_MCAN_TXBCF ro — MCAN Tx Buffer Cancellation Finished
    [n] CF{n} (n=1..31) — Cancellation Finished {n}. See description for bit 0.
    [0] CF0 — Cancellation Finished 0. Each Tx Buffer has its own Cancellation Finished bit. The bits are set when the corresponding TXBRP bit is cleared after a cancellation was requested via TXBCR. In case the corresponding TXBRP bit was not set at the point of cancellation, CF is set immediately. The bits are reset when a new transmission is requested by writing a '1' to the corresponding bit of register TXBAR. 0 No transmit buffer cancellation 1 Transmit buffer cancellation finished
  0xE0 CANFD0_MCAN_TXBTIE — MCAN Tx Buffer Transmission Interrupt Enable
    [n] TIE{n} (n=0..31) — Transmission Interrupt Enable {n}. Each Tx Buffer has its own Transmission Interrupt Enable bit. 0 Transmission interrupt disabled 1 Transmission interrupt enable
  0xE4 CANFD0_MCAN_TXBCIE — MCAN Tx Buffer Cancellation Finished Interrupt Enable
    [n] CFIE{n} (n=0..31) — Cancellation Finished Interrupt Enable {n}. Each Tx Buffer has its own Cancellation Finished Interrupt Enable bit. 0 Cancellation finished interrupt disabled 1 Cancellation finished interrupt enabled
  0xF0 CANFD0_MCAN_TXEFC — MCAN Tx Event FIFO Configuration
    [29:24] EFWM — Event FIFO Watermark 0 Watermark interrupt disabled 1-32 Level for Tx Event FIFO watermark interrupt (IR.TEFW) >32 Watermark interrupt disabled
    [21:16] EFS — Event FIFO Size. The Tx Event FIFO elements are indexed from 0 to EFS - 1. 0 Tx Event FIFO disabled 1-32 Number of Tx Event FIFO elements >32 Values greater than 32 are interpreted as 32
    [15:2] EFSA — Event FIFO Start Address. Start address of Tx Event FIFO in Message RAM (32-bit word address).
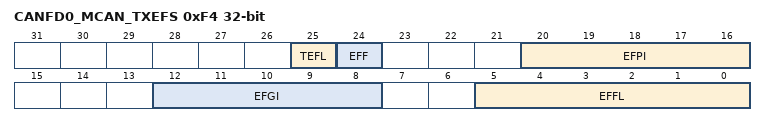
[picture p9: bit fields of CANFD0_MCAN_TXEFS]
  0xF4 CANFD0_MCAN_TXEFS ro — MCAN Tx Event FIFO Status
    [25] TEFL — Tx Event FIFO Element Lost. This bit is a copy of interrupt flag IR.TEFL. When IR.TEFL is reset, this bit is also reset. 0 No Tx Event FIFO element lost 1 Tx Event FIFO element lost, also set after write attempt to Tx Event FIFO of size zero.
    [24] EFF — Event FIFO Full 0 Tx Event FIFO not full 1 Tx Event FIFO full
    [20:16] EFPI — Event FIFO Put Index.Tx Event FIFO write index pointer, range 0 to 31.
    [12:8] EFGI — Event FIFO Get Index. Tx Event FIFO read index pointer, range 0 to 31.
    [5:0] EFFL — Event FIFO Fill Level. Number of elements stored in Tx Event FIFO, range 0 to 32.
  0xF8 CANFD0_MCAN_TXEFA — MCAN Tx Event FIFO Acknowledge
    [4:0] EFAI — Event FIFO Acknowledge Index. After the Host has read an element or a sequence of elements from the Tx Event FIFO it has to write the index of the last element read from Tx Event FIFO to EFAI. This will set the Tx Event FIFO Get Index TXEFS.EFGI to EFAI + 1 and update the Event FIFO Fill Level TXEFS.EFFL.
